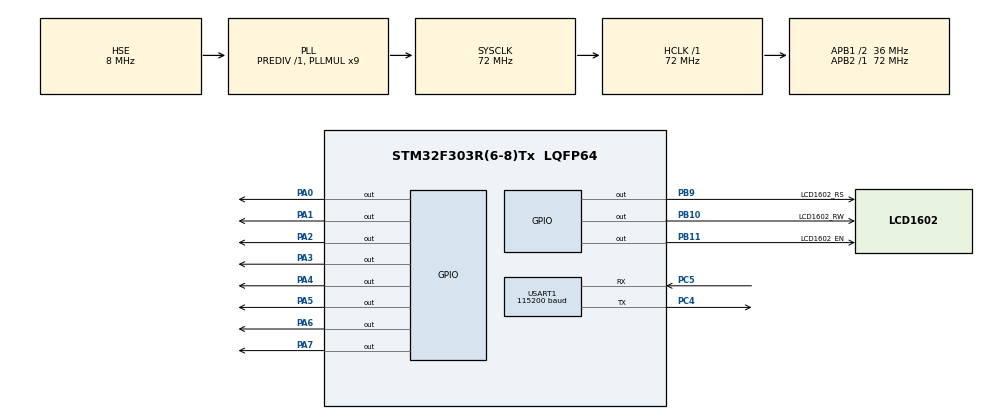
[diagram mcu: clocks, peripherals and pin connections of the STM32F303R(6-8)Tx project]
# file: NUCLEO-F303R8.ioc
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Mcu.Family=STM32F3
Mcu.Name=STM32F303R(6-8)Tx
Mcu.Package=LQFP64
NVIC.PriorityGroup=NVIC_PRIORITYGROUP_4
PA0.Signal=GPIO_Output
PA1.Signal=GPIO_Output
PA13.Mode=Serial_Wire
PA13.Signal=SYS_JTMS-SWDIO
PA14.Mode=Serial_Wire
PA14.Signal=SYS_JTCK-SWCLK
PA2.Signal=GPIO_Output
PA3.Signal=GPIO_Output
PA4.Signal=GPIO_Output
PA5.Signal=GPIO_Output
PA6.Signal=GPIO_Output
PA7.Signal=GPIO_Output
PB10.GPIO_Label=LCD1602_RW
PB10.Signal=GPIO_Output
PB11.GPIO_Label=LCD1602_EN
PB11.Signal=GPIO_Output
PB9.GPIO_Label=LCD1602_RS
PB9.Signal=GPIO_Output
PC4.Mode=Asynchronous
PC4.Signal=USART1_TX
PC5.Mode=Asynchronous
PC5.Signal=USART1_RX
PF0\ /\ OSC_IN.Mode=HSE-External-Oscillator
PF0\ /\ OSC_IN.Signal=RCC_OSC_IN
PF1\ /\ OSC_OUT.Mode=HSE-External-Oscillator
PF1\ /\ OSC_OUT.Signal=RCC_OSC_OUT
ProjectManager.HeapSize=0x200
ProjectManager.StackSize=0x400
ProjectManager.TargetToolchain=CMake
RCC.AHBFreq_Value=72000000
RCC.APB1CLKDivider=RCC_HCLK_DIV2
RCC.APB1Freq_Value=36000000
RCC.APB1TimFreq_Value=72000000
RCC.APB2Freq_Value=72000000
RCC.APB2TimFreq_Value=72000000
RCC.CortexFreq_Value=72000000
RCC.HCLKFreq_Value=72000000
RCC.HSE_VALUE=8000000
RCC.HSI_VALUE=8000000
RCC.LSE_VALUE=32768
RCC.PLLMUL=RCC_PLL_MUL9
RCC.PLLSourceVirtual=RCC_PLLSOURCE_HSE
RCC.SYSCLKFreq_VALUE=72000000
RCC.SYSCLKSourceVirtual=RCC_SYSCLKSOURCE_PLLCLK
TIM6.Prescaler=72-1
USART1.BaudRate=115200
USART1.VirtualMode-Asynchronous=VM_ASYNC
VP_TIM6_VS_ClockSourceINT.Mode=Enable_Timer
board=custom

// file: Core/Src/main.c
/* USER CODE BEGIN Header */
/**
  ******************************************************************************
  * @file           : main.c
  * @brief          : Main program body
  ******************************************************************************
  * @attention
  *
  * Copyright (c) 2024 STMicroelectronics.
  * All rights reserved.
  *
  * This software is licensed under terms that can be found in the LICENSE file
  * in the root directory of this software component.
  * If no LICENSE file comes with this software, it is provided AS-IS.
  *
  ******************************************************************************
  */
/* USER CODE END Header */
#include "main.h"
#include "tim.h"
#include "usart.h"
#include "gpio.h"

/* USER CODE BEGIN Includes */
#include "lcd1602.h"
/* USER CODE END Includes */

/* USER CODE BEGIN PV */

int count = 0;
extern TIM_HandleTypeDef htim6;

/* USER CODE END PV */

void SystemClock_Config(void);

int main(void)
{

  /* MCU Configuration--------------------------------------------------------*/

  /* Reset of all peripherals, Initializes the Flash interface and the Systick. */
  HAL_Init();

  /* Configure the system clock */
  SystemClock_Config();

  /* Initialize all configured peripherals */
  MX_GPIO_Init();
  MX_USART1_UART_Init();
  MX_TIM6_Init();
  /* USER CODE BEGIN 2 */
  HAL_TIM_Base_Start(&htim6);

  lcd_init();
  lcd_send_string("1234567890");
  /* USER CODE END 2 */

  /* Infinite loop */
  while (1)
  {

  }
}

void SystemClock_Config(void)
{
  RCC_OscInitTypeDef RCC_OscInitStruct = {0};
  RCC_ClkInitTypeDef RCC_ClkInitStruct = {0};
  RCC_PeriphCLKInitTypeDef PeriphClkInit = {0};

  /** Initializes the RCC Oscillators according to the specified parameters
  * in the RCC_OscInitTypeDef structure.
  */
  RCC_OscInitStruct.OscillatorType = RCC_OSCILLATORTYPE_HSE;
  RCC_OscInitStruct.HSEState = RCC_HSE_ON;
  RCC_OscInitStruct.HSEPredivValue = RCC_HSE_PREDIV_DIV1;
  RCC_OscInitStruct.HSIState = RCC_HSI_ON;
  RCC_OscInitStruct.PLL.PLLState = RCC_PLL_ON;
  RCC_OscInitStruct.PLL.PLLSource = RCC_PLLSOURCE_HSE;
  RCC_OscInitStruct.PLL.PLLMUL = RCC_PLL_MUL9;
  if (HAL_RCC_OscConfig(&RCC_OscInitStruct) != HAL_OK)
  {
    Error_Handler();
  }

  /** Initializes the CPU, AHB and APB buses clocks
  */
  RCC_ClkInitStruct.ClockType = RCC_CLOCKTYPE_HCLK|RCC_CLOCKTYPE_SYSCLK
                              |RCC_CLOCKTYPE_PCLK1|RCC_CLOCKTYPE_PCLK2;
  RCC_ClkInitStruct.SYSCLKSource = RCC_SYSCLKSOURCE_PLLCLK;
  RCC_ClkInitStruct.AHBCLKDivider = RCC_SYSCLK_DIV1;
  RCC_ClkInitStruct.APB1CLKDivider = RCC_HCLK_DIV2;
  RCC_ClkInitStruct.APB2CLKDivider = RCC_HCLK_DIV1;

  if (HAL_RCC_ClockConfig(&RCC_ClkInitStruct, FLASH_LATENCY_2) != HAL_OK)
  {
    Error_Handler();
  }
  PeriphClkInit.PeriphClockSelection = RCC_PERIPHCLK_USART1;
  PeriphClkInit.Usart1ClockSelection = RCC_USART1CLKSOURCE_PCLK1;
  if (HAL_RCCEx_PeriphCLKConfig(&PeriphClkInit) != HAL_OK)
  {
    Error_Handler();
  }
}

void Error_Handler(void)
{
  __disable_irq();
  while (1)
  {
  }
}
